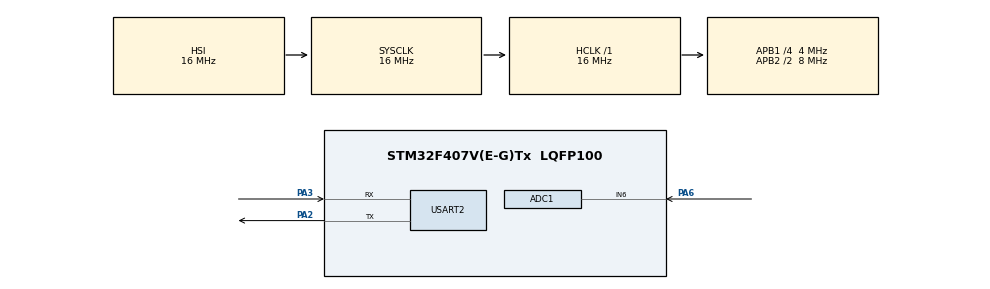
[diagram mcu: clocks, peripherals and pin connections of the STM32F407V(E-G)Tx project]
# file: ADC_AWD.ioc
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ADC1.Channel-2\#ChannelRegularConversion=ADC_CHANNEL_6
ADC1.ContinuousConvMode=ENABLE
ADC1.EnableAnalogWatchDog=true
ADC1.HighThreshold=3000
ADC1.ITMode=ENABLE
ADC1.NbrOfConversionFlag=1
ADC1.Rank-2\#ChannelRegularConversion=1
ADC1.SamplingTime-2\#ChannelRegularConversion=ADC_SAMPLETIME_144CYCLES
ADC1.WatchdogChannel=ADC_CHANNEL_6
ADC1.master=1
Mcu.Family=STM32F4
Mcu.Name=STM32F407V(E-G)Tx
Mcu.Package=LQFP100
NVIC.ADC_IRQn=true\:0\:0\:false\:false\:true\:true\:true\:true
NVIC.PriorityGroup=NVIC_PRIORITYGROUP_0
PA2.Mode=Asynchronous
PA2.Signal=USART2_TX
PA3.Mode=Asynchronous
PA3.Signal=USART2_RX
PA6.Signal=ADCx_IN6
ProjectManager.HeapSize=0x200
ProjectManager.StackSize=0x400
ProjectManager.TargetToolchain=STM32CubeIDE
RCC.48MHZClocksFreq_Value=14285714.285714285
RCC.AHBFreq_Value=16000000
RCC.APB1CLKDivider=RCC_HCLK_DIV4
RCC.APB1Freq_Value=4000000
RCC.APB1TimFreq_Value=8000000
RCC.APB2CLKDivider=RCC_HCLK_DIV2
RCC.APB2Freq_Value=8000000
RCC.APB2TimFreq_Value=16000000
RCC.CortexFreq_Value=16000000
RCC.HCLKFreq_Value=16000000
RCC.HSE_VALUE=8000000
RCC.HSI_VALUE=16000000
RCC.LSE_VALUE=32768
RCC.PLLM=8
RCC.PLLN=50
RCC.PLLQ=7
RCC.SYSCLKFreq_VALUE=16000000
RCC.VCOOutputFreq_Value=100000000
SH.ADCx_IN6.0=ADC1_IN6,IN6
USART2.VirtualMode=VM_ASYNC
board=STM32F407G-DISC1

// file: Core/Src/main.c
/* USER CODE BEGIN Header */
/**
  ******************************************************************************
  * @file           : main.c
  * @brief          : Main program body
  ******************************************************************************
  * @attention
  *
  * Copyright (c) 2024 STMicroelectronics.
  * All rights reserved.
  *
  * This software is licensed under terms that can be found in the LICENSE file
  * in the root directory of this software component.
  * If no LICENSE file comes with this software, it is provided AS-IS.
  *
  ******************************************************************************
  */
/* USER CODE END Header */
#include "main.h"

/* USER CODE BEGIN Includes */
#include <stdio.h>
#include <string.h>
/* USER CODE END Includes */

ADC_HandleTypeDef hadc1;

UART_HandleTypeDef huart2;

/* USER CODE BEGIN PV */
__IO uint8_t AWD_Flag = RESET;
__IO uint16_t count =0;
/* USER CODE END PV */

void SystemClock_Config(void);
static void MX_GPIO_Init(void);
static void MX_ADC1_Init(void);
static void MX_USART2_UART_Init(void);
/* USER CODE BEGIN PFP */
#ifdef __GNUC__
#define PUTCHAR_PROTOTYPE int __io_putchar(int ch)
#else
#define PUTCHAR_PROTOTYPE int fputc(int ch, FILE *f)
#endif

PUTCHAR_PROTOTYPE
{
  HAL_UART_Transmit(&huart2, (uint8_t *)&ch, 1, HAL_MAX_DELAY);
  return ch;
}
/* USER CODE END PFP */

int main(void)
{

  /* MCU Configuration--------------------------------------------------------*/

  /* Reset of all peripherals, Initializes the Flash interface and the Systick. */
  HAL_Init();

  /* Configure the system clock */
  SystemClock_Config();

  /* Initialize all configured peripherals */
  MX_GPIO_Init();
  MX_ADC1_Init();
  MX_USART2_UART_Init();
  /* USER CODE BEGIN 2 */
  if(HAL_ADC_Start_IT(&hadc1) != HAL_OK)
  {
	  Error_Handler();
  }
  /* USER CODE END 2 */

  /* Infinite loop */
  /* USER CODE BEGIN WHILE */
  while (1)
  {
	  	  if(AWD_Flag == SET)
	  	  {
	  		  printf("Outside the Window\r\n");
	  		  // Polling For value
	  		  HAL_ADC_PollForConversion(&hadc1, HAL_MAX_DELAY);
	  		  count = HAL_ADC_GetValue(&hadc1);
	  		  printf("count : %d\r\n",count);

	  	  }
	  	  else
	  	  {
	  		  printf("Inside the Window\r\n");
	  	  }
	  	  AWD_Flag = RESET;
	  	  HAL_Delay(1000);// if delay removed then it wont reset;
    /* USER CODE END WHILE */

  }
}

void SystemClock_Config(void)
{
  RCC_OscInitTypeDef RCC_OscInitStruct = {0};
  RCC_ClkInitTypeDef RCC_ClkInitStruct = {0};

  /** Configure the main internal regulator output voltage
  */
  __HAL_RCC_PWR_CLK_ENABLE();
  __HAL_PWR_VOLTAGESCALING_CONFIG(PWR_REGULATOR_VOLTAGE_SCALE1);

  /** Initializes the RCC Oscillators according to the specified parameters
  * in the RCC_OscInitTypeDef structure.
  */
  RCC_OscInitStruct.OscillatorType = RCC_OSCILLATORTYPE_HSI;
  RCC_OscInitStruct.HSIState = RCC_HSI_ON;
  RCC_OscInitStruct.HSICalibrationValue = RCC_HSICALIBRATION_DEFAULT;
  RCC_OscInitStruct.PLL.PLLState = RCC_PLL_NONE;
  if (HAL_RCC_OscConfig(&RCC_OscInitStruct) != HAL_OK)
  {
    Error_Handler();
  }

  /** Initializes the CPU, AHB and APB buses clocks
  */
  RCC_ClkInitStruct.ClockType = RCC_CLOCKTYPE_HCLK|RCC_CLOCKTYPE_SYSCLK
                              |RCC_CLOCKTYPE_PCLK1|RCC_CLOCKTYPE_PCLK2;
  RCC_ClkInitStruct.SYSCLKSource = RCC_SYSCLKSOURCE_HSI;
  RCC_ClkInitStruct.AHBCLKDivider = RCC_SYSCLK_DIV1;
  RCC_ClkInitStruct.APB1CLKDivider = RCC_HCLK_DIV4;
  RCC_ClkInitStruct.APB2CLKDivider = RCC_HCLK_DIV2;

  if (HAL_RCC_ClockConfig(&RCC_ClkInitStruct, FLASH_LATENCY_0) != HAL_OK)
  {
    Error_Handler();
  }
}

static void MX_ADC1_Init(void)
{

  ADC_AnalogWDGConfTypeDef AnalogWDGConfig = {0};
  ADC_ChannelConfTypeDef sConfig = {0};

  /** Configure the global features of the ADC (Clock, Resolution, Data Alignment and number of conversion)
  */
  hadc1.Instance = ADC1;
  hadc1.Init.ClockPrescaler = ADC_CLOCK_SYNC_PCLK_DIV2;
  hadc1.Init.Resolution = ADC_RESOLUTION_12B;
  hadc1.Init.ScanConvMode = DISABLE;
  hadc1.Init.ContinuousConvMode = ENABLE;
  hadc1.Init.DiscontinuousConvMode = DISABLE;
  hadc1.Init.ExternalTrigConvEdge = ADC_EXTERNALTRIGCONVEDGE_NONE;
  hadc1.Init.ExternalTrigConv = ADC_SOFTWARE_START;
  hadc1.Init.DataAlign = ADC_DATAALIGN_RIGHT;
  hadc1.Init.NbrOfConversion = 1;
  hadc1.Init.DMAContinuousRequests = DISABLE;
  hadc1.Init.EOCSelection = ADC_EOC_SINGLE_SEQ_CONV;
  if (HAL_ADC_Init(&hadc1) != HAL_OK)
  {
    Error_Handler();
  }

  /** Configure the analog watchdog
  */
  AnalogWDGConfig.WatchdogMode = ADC_ANALOGWATCHDOG_SINGLE_REG;
  AnalogWDGConfig.HighThreshold = 3000;
  AnalogWDGConfig.LowThreshold = 0;
  AnalogWDGConfig.Channel = ADC_CHANNEL_6;
  AnalogWDGConfig.ITMode = ENABLE;
  if (HAL_ADC_AnalogWDGConfig(&hadc1, &AnalogWDGConfig) != HAL_OK)
  {
    Error_Handler();
  }

  /** Configure for the selected ADC regular channel its corresponding rank in the sequencer and its sample time.
  */
  sConfig.Channel = ADC_CHANNEL_6;
  sConfig.Rank = 1;
  sConfig.SamplingTime = ADC_SAMPLETIME_144CYCLES;
  if (HAL_ADC_ConfigChannel(&hadc1, &sConfig) != HAL_OK)
  {
    Error_Handler();
  }

}

static void MX_USART2_UART_Init(void)
{

  huart2.Instance = USART2;
  huart2.Init.BaudRate = 115200;
  huart2.Init.WordLength = UART_WORDLENGTH_8B;
  huart2.Init.StopBits = UART_STOPBITS_1;
  huart2.Init.Parity = UART_PARITY_NONE;
  huart2.Init.Mode = UART_MODE_TX_RX;
  huart2.Init.HwFlowCtl = UART_HWCONTROL_NONE;
  huart2.Init.OverSampling = UART_OVERSAMPLING_16;
  if (HAL_UART_Init(&huart2) != HAL_OK)
  {
    Error_Handler();
  }

}

static void MX_GPIO_Init(void)
{

  /* GPIO Ports Clock Enable */
  __HAL_RCC_GPIOA_CLK_ENABLE();

}

/* USER CODE BEGIN 4 */
void HAL_ADC_LevelOutOfWindowCallback(ADC_HandleTypeDef *hadc)
{
//	printf("Callback\r\n");
	AWD_Flag = SET;
}

//void HAL_ADC_ConvCpltCallback(ADC_HandleTypeDef *hadc)
//{
////	  if(AWD_Flag == SET)
////	  {
////		  printf("Outside the Window\r\n");
////	  }
////	  else
////	  {
////		 printf("Outside the Window\r\n");
////	  }
////	  AWD_Flag = RESET;
//}
/* USER CODE END 4 */

void Error_Handler(void)
{
  __disable_irq();
  while (1)
  {
  }
}
